AUTOSAR XML (schema 4-0-3)
package /App_ComM
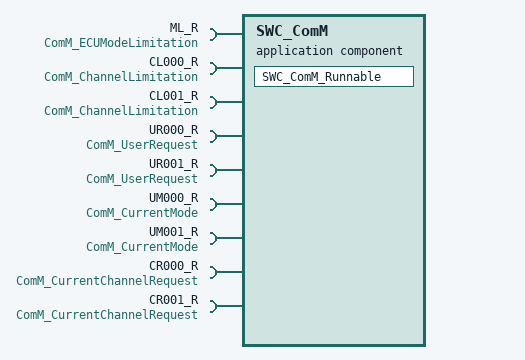
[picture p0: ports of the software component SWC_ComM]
  application sw component type SWC_ComM
    9 x require port:
      ML_R: required-com-specs=[GetStatus, LimitECUToNoComMode, ReadInhibitCounter, ResetInhibitCounter, SetECUGroupClassification], required-interface=ComM_ECUModeLimitation
      CL000_R: required-com-specs=[LimitChannelToNoComMode, PreventWakeUp, GetInhibitionStatus, GetState], required-interface=ComM_ChannelLimitation
      CL001_R: required-com-specs=[LimitChannelToNoComMode, PreventWakeUp, GetInhibitionStatus, GetState], required-interface=ComM_ChannelLimitation
      UR000_R: required-com-specs=[RequestComMode, GetCurrentComMode, GetRequestedComMode], required-interface=ComM_UserRequest
      UR001_R: required-com-specs=[RequestComMode, GetCurrentComMode, GetRequestedComMode], required-interface=ComM_UserRequest
      UM000_R: mode-switch-receiver-com-spec{enhanced-mode-api=false, supports-asynchronous-mode-switch=true}, required-interface=ComM_CurrentMode
      UM001_R: mode-switch-receiver-com-spec{enhanced-mode-api=false, supports-asynchronous-mode-switch=true}, required-interface=ComM_CurrentMode
      CR000_R: nonqueued-receiver-com-spec=fullComRequestors, required-interface=ComM_CurrentChannelRequest
      CR001_R: nonqueued-receiver-com-spec=fullComRequestors, required-interface=ComM_CurrentChannelRequest
    behavior SwcIB_ComM
      runnable SWC_ComM_Runnable: can-be-invoked-concurrently=true, mode-access-points=[UM000_R.currentMode, UM001_R.currentMode]
        data-receive-point-by-arguments:
          access VariableAccess_0: accessed-variable=CR000_R.fullComRequestors, scope=COMMUNICATION-INTER-ECU
          access VariableAccess_1: accessed-variable=CR001_R.fullComRequestors, scope=COMMUNICATION-INTER-ECU
        19 x sync call:
          SyncServerCallPoint_GetStatus_ML: operation=ML_R.GetStatus
          SyncServerCallPoint_LimitECUToNoComMode_ML: operation=ML_R.LimitECUToNoComMode
          SyncServerCallPoint_ReadInhibitCounter_ML: operation=ML_R.ReadInhibitCounter
          SyncServerCallPoint_ResetInhibitCounter_ML: operation=ML_R.ResetInhibitCounter
          SyncServerCallPoint_SetECUGroupClassification_ML: operation=ML_R.SetECUGroupClassification
          SyncServerCallPoint_LimitChannelToNoComMode_CL000: operation=CL000_R.LimitChannelToNoComMode
          SyncServerCallPoint_LimitChannelToNoComMode_CL001: operation=CL001_R.LimitChannelToNoComMode
          SyncServerCallPoint_GetInhibitionStatus_CL000: operation=CL000_R.GetInhibitionStatus
          SyncServerCallPoint_GetInhibitionStatus_CL001: operation=CL001_R.GetInhibitionStatus
          SyncServerCallPoint_PreventWakeUp_CL000: operation=CL000_R.PreventWakeUp
          SyncServerCallPoint_PreventWakeUp_CL001: operation=CL001_R.PreventWakeUp
          SyncServerCallPoint_GetState_CL000: operation=CL000_R.GetState
          SyncServerCallPoint_GetState_CL001: operation=CL001_R.GetState
          SyncServerCallPoint_RequestComMode_UR000: operation=UR000_R.RequestComMode
          SyncServerCallPoint_RequestComMode_UR001: operation=UR001_R.RequestComMode
          SyncServerCallPoint_GetCurrentComMode_UR000: operation=UR000_R.GetCurrentComMode
          SyncServerCallPoint_GetCurrentComMode_UR001: operation=UR001_R.GetCurrentComMode
          SyncServerCallPoint_GetRequestedComMode_UR000: operation=UR000_R.GetRequestedComMode
          SyncServerCallPoint_GetRequestedComMode_UR001: operation=UR001_R.GetRequestedComMode
